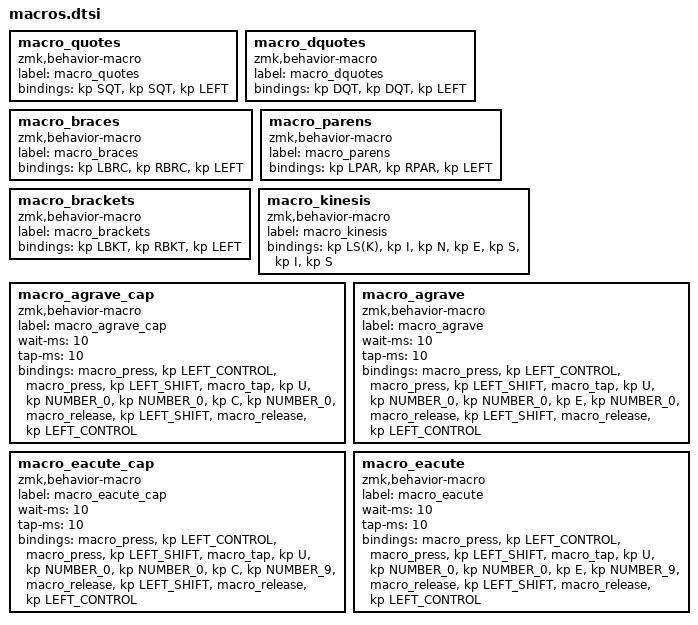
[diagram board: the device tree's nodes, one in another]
macro_quotes: macro_quotes{
compatible = "zmk,behavior-macro";
label = "macro_quotes";
#binding-cells = <0>;
bindings = <&kp SQT>, <&kp SQT>, <&kp LEFT>;
};
macro_dquotes: macro_dquotes{
compatible = "zmk,behavior-macro";
label = "macro_dquotes";
#binding-cells = <0>;
bindings = <&kp DQT>, <&kp DQT>, <&kp LEFT>;
};
macro_braces: macro_braces{
compatible = "zmk,behavior-macro";
label = "macro_braces";
#binding-cells = <0>;
bindings = <&kp LBRC>, <&kp RBRC>, <&kp LEFT>;
};
macro_parens: macro_parens{
compatible = "zmk,behavior-macro";
label = "macro_parens";
#binding-cells = <0>;
bindings = <&kp LPAR>, <&kp RPAR>, <&kp LEFT>;
};
macro_brackets: macro_brackets{
compatible = "zmk,behavior-macro";
label = "macro_brackets";
#binding-cells = <0>;
bindings = <&kp LBKT>, <&kp RBKT>, <&kp LEFT>;
};
macro_kinesis: macro_kinesis{
compatible = "zmk,behavior-macro";
label = "macro_kinesis";
#binding-cells = <0>;
bindings = <&kp LS(K)>, <&kp I>, <&kp N>, <&kp E>, <&kp S>, <&kp I>, <&kp S>;
};
macro_agrave_cap: macro_agrave_cap{
compatible = "zmk,behavior-macro";
label = "macro_agrave_cap";
#binding-cells = <0>;
wait-ms = <10>;
tap-ms = <10>;
bindings 
  = <&macro_press &kp LEFT_CONTROL>, 
    <&macro_press &kp LEFT_SHIFT>, 
    <&macro_tap &kp U &kp NUMBER_0 &kp NUMBER_0 &kp C &kp NUMBER_0>,
    <&macro_release &kp LEFT_SHIFT>,
    <&macro_release &kp LEFT_CONTROL>
    ;
};
macro_agrave: macro_agrave{
compatible = "zmk,behavior-macro";
label = "macro_agrave";
#binding-cells = <0>;
wait-ms = <10>;
tap-ms = <10>;
bindings 
  = <&macro_press &kp LEFT_CONTROL>, 
    <&macro_press &kp LEFT_SHIFT>, 
    <&macro_tap &kp U &kp NUMBER_0 &kp NUMBER_0 &kp E &kp NUMBER_0>,
    <&macro_release &kp LEFT_SHIFT>,
    <&macro_release &kp LEFT_CONTROL>
    ;
};
macro_eacute_cap: macro_eacute_cap{
compatible = "zmk,behavior-macro";
label = "macro_eacute_cap";
#binding-cells = <0>;
wait-ms = <10>;
tap-ms = <10>;
bindings 
  = <&macro_press &kp LEFT_CONTROL>, 
    <&macro_press &kp LEFT_SHIFT>, 
    <&macro_tap &kp U &kp NUMBER_0 &kp NUMBER_0 &kp C &kp NUMBER_9>,
    <&macro_release &kp LEFT_SHIFT>,
    <&macro_release &kp LEFT_CONTROL>
    ;
};
macro_eacute: macro_eacute{
compatible = "zmk,behavior-macro";
label = "macro_eacute";
#binding-cells = <0>;
wait-ms = <10>;
tap-ms = <10>;
bindings 
  = <&macro_press &kp LEFT_CONTROL>, 
    <&macro_press &kp LEFT_SHIFT>, 
    <&macro_tap &kp U &kp NUMBER_0 &kp NUMBER_0 &kp E &kp NUMBER_9>,
    <&macro_release &kp LEFT_SHIFT>,
    <&macro_release &kp LEFT_CONTROL>
    ;
};
